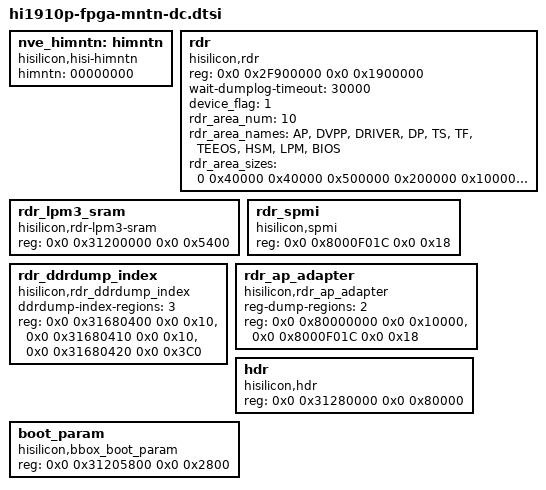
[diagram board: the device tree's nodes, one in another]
/*
 * Hisilicon Ltd. Davinci SoC
 */

	nve_himntn:himntn {
		compatible = "hisilicon,hisi-himntn";
		himntn = "00000000";
	};

	rdr {
		compatible = "hisilicon,rdr";
		reg = <0x0 0x2F900000 0x0 0x1900000>;/*rdr_base_addr*/
		wait-dumplog-timeout = <30000>;
		device_flag = <1>;/*0:chip 1:fpga 2:esl*/
		rdr_area_num = <10>;
		rdr_area_names = "AP", "DVPP", "DRIVER", "DP", "TS", "TF", "TEEOS", "HSM", "LPM", "BIOS";
		rdr_area_sizes = <0 0x40000 0x40000 0x500000 0x200000 0x10000 0x20000 0x50000 0x90000 0x50000>;
		status = "ok";
	};

	rdr_lpm3_sram {
		compatible = "hisilicon,rdr-lpm3-sram";
		reg = <0x0 0x31200000 0x0 0x5400>;/*lpm3_sram_base_addr*/
		status = "ok";
	};

	rdr_spmi {
		compatible = "hisilicon,spmi";
		reg = <0x0 0x8000F01C 0x0 0x18>;/*pmu_base_addr*/
		status = "ok";
	};

	rdr_ddrdump_index {
		compatible = "hisilicon,rdr_ddrdump_index";
		ddrdump-index-regions = <3>;
		reg-names = "ts", "aicpu", "kernel";
		reg = <0x0 0x31680400 0x0 0x10>,
			<0x0 0x31680410 0x0 0x10>,
			<0x0 0x31680420 0x0 0x3C0>;
		status = "ok";
	};

	rdr_ap_adapter {
		compatible = "hisilicon,rdr_ap_adapter";
		reg-dump-regions = <2>; /*NOTE:should be less than 10*/
		reg-names = "sctrl", "pmu";
		reg = <0x0 0x80000000 0x0 0x10000>,
			<0x0 0x8000F01C 0x0 0x18>;
		status = "ok";
	};

	hdr {
		compatible = "hisilicon,hdr";
		reg = <0x0 0x31280000 0x0 0x80000>;
		status = "ok";
	};

	boot_param {
		compatible = "hisilicon,bbox_boot_param";
		reg = <0x0 0x31205800 0x0 0x2800>;
		status = "ok";
	};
